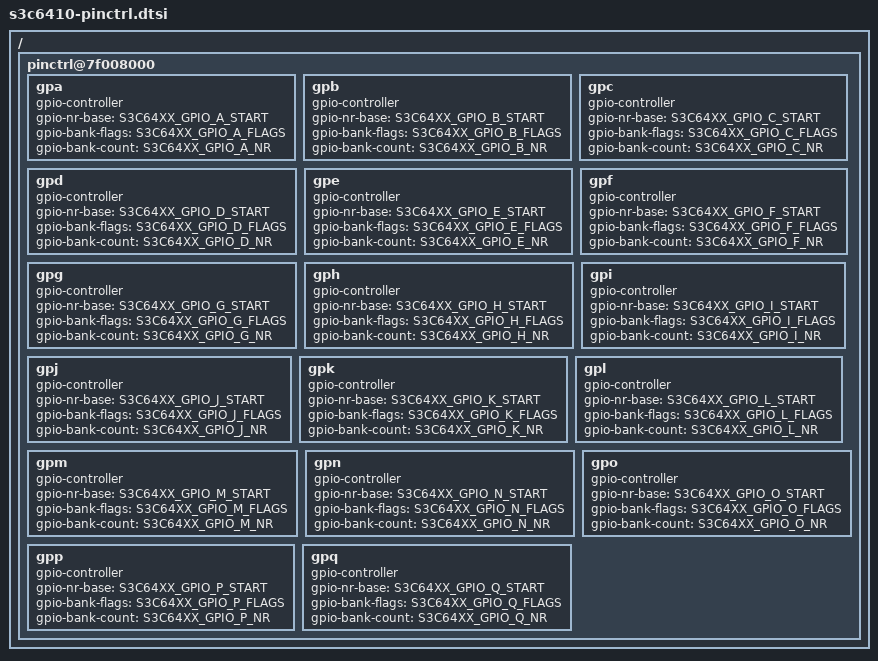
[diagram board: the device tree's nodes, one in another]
// SPDX-License-Identifier: GPL-2.0+
/*
 * U-Boot additions to enable a generic Exynos GPIO driver
 *
 * Copyright (c) 2014 Google, Inc
 *
 */
#define __DTS_S3C6410_PINCTRL__
#include <asm/arch/gpio.h>

/ {
	pinctrl@7f008000 {
		gpa: gpa {
			gpio-controller;
			#gpio-cells = <2>;
			gpio-nr-base = <S3C64XX_GPIO_A_START>;
			gpio-bank-flags = <S3C64XX_GPIO_A_FLAGS>;
			gpio-bank-count = <S3C64XX_GPIO_A_NR>;
		};

		gpb: gpb {
			gpio-controller;
			#gpio-cells = <2>;
			gpio-nr-base = <S3C64XX_GPIO_B_START>;
			gpio-bank-flags = <S3C64XX_GPIO_B_FLAGS>;
			gpio-bank-count = <S3C64XX_GPIO_B_NR>;
		};

		gpc: gpc {
			gpio-controller;
			#gpio-cells = <2>;
			gpio-nr-base = <S3C64XX_GPIO_C_START>;
			gpio-bank-flags = <S3C64XX_GPIO_C_FLAGS>;
			gpio-bank-count = <S3C64XX_GPIO_C_NR>;
		};

		gpd: gpd {
			gpio-controller;
			#gpio-cells = <2>;
			gpio-nr-base = <S3C64XX_GPIO_D_START>;
			gpio-bank-flags = <S3C64XX_GPIO_D_FLAGS>;
			gpio-bank-count = <S3C64XX_GPIO_D_NR>;
		};

		gpe: gpe {
			gpio-controller;
			#gpio-cells = <2>;
			gpio-nr-base = <S3C64XX_GPIO_E_START>;
			gpio-bank-flags = <S3C64XX_GPIO_E_FLAGS>;
			gpio-bank-count = <S3C64XX_GPIO_E_NR>;
		};

		gpf: gpf {
			gpio-controller;
			#gpio-cells = <2>;
			gpio-nr-base = <S3C64XX_GPIO_F_START>;
			gpio-bank-flags = <S3C64XX_GPIO_F_FLAGS>;
			gpio-bank-count = <S3C64XX_GPIO_F_NR>;
		};

		gpg: gpg {
			gpio-controller;
			#gpio-cells = <2>;
			gpio-nr-base = <S3C64XX_GPIO_G_START>;
			gpio-bank-flags = <S3C64XX_GPIO_G_FLAGS>;
			gpio-bank-count = <S3C64XX_GPIO_G_NR>;
		};

		gph: gph {
			gpio-controller;
			#gpio-cells = <2>;
			gpio-nr-base = <S3C64XX_GPIO_H_START>;
			gpio-bank-flags = <S3C64XX_GPIO_H_FLAGS>;
			gpio-bank-count = <S3C64XX_GPIO_H_NR>;
		};

		gpi: gpi {
			gpio-controller;
			#gpio-cells = <2>;
			gpio-nr-base = <S3C64XX_GPIO_I_START>;
			gpio-bank-flags = <S3C64XX_GPIO_I_FLAGS>;
			gpio-bank-count = <S3C64XX_GPIO_I_NR>;
		};

		gpj: gpj {
			gpio-controller;
			#gpio-cells = <2>;
			gpio-nr-base = <S3C64XX_GPIO_J_START>;
			gpio-bank-flags = <S3C64XX_GPIO_J_FLAGS>;
			gpio-bank-count = <S3C64XX_GPIO_J_NR>;
		};

		gpk: gpk {
			gpio-controller;
			#gpio-cells = <2>;
			gpio-nr-base = <S3C64XX_GPIO_K_START>;
			gpio-bank-flags = <S3C64XX_GPIO_K_FLAGS>;
			gpio-bank-count = <S3C64XX_GPIO_K_NR>;
		};

		gpl: gpl {
			gpio-controller;
			#gpio-cells = <2>;
			gpio-nr-base = <S3C64XX_GPIO_L_START>;
			gpio-bank-flags = <S3C64XX_GPIO_L_FLAGS>;
			gpio-bank-count = <S3C64XX_GPIO_L_NR>;
		};

		gpm: gpm {
			gpio-controller;
			#gpio-cells = <2>;
			gpio-nr-base = <S3C64XX_GPIO_M_START>;
			gpio-bank-flags = <S3C64XX_GPIO_M_FLAGS>;
			gpio-bank-count = <S3C64XX_GPIO_M_NR>;
		};

		gpn: gpn {
			gpio-controller;
			#gpio-cells = <2>;
			gpio-nr-base = <S3C64XX_GPIO_N_START>;
			gpio-bank-flags = <S3C64XX_GPIO_N_FLAGS>;
			gpio-bank-count = <S3C64XX_GPIO_N_NR>;
		};

		gpo: gpo {
			gpio-controller;
			#gpio-cells = <2>;
			gpio-nr-base = <S3C64XX_GPIO_O_START>;
			gpio-bank-flags = <S3C64XX_GPIO_O_FLAGS>;
			gpio-bank-count = <S3C64XX_GPIO_O_NR>;
		};

		gpp: gpp {
			gpio-controller;
			#gpio-cells = <2>;
			gpio-nr-base = <S3C64XX_GPIO_P_START>;
			gpio-bank-flags = <S3C64XX_GPIO_P_FLAGS>;
			gpio-bank-count = <S3C64XX_GPIO_P_NR>;
		};
		
		gpq: gpq {
			gpio-controller;
			#gpio-cells = <2>;
			gpio-nr-base = <S3C64XX_GPIO_Q_START>;
			gpio-bank-flags = <S3C64XX_GPIO_Q_FLAGS>;
			gpio-bank-count = <S3C64XX_GPIO_Q_NR>;
		};
	};
};
